# RL7005_IP_SVD register map
Vendor: Realtek
Registers are 32-bit, read-write, reset 0x0 unless marked. A register's access mark holds for its fields unless they carry their own. Offsets are from the block's base; [hi:lo] are bit positions; {n}, {i} and the like mark numbered series.

## UVC_REG
Base 0x400B1000
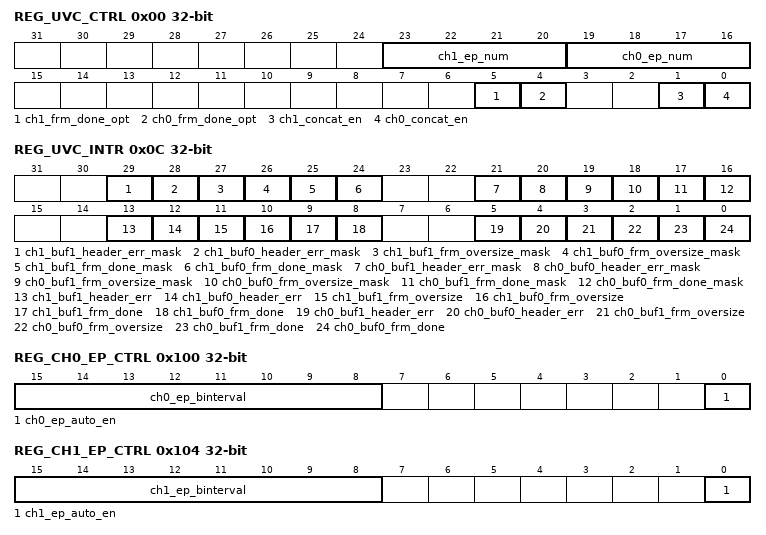
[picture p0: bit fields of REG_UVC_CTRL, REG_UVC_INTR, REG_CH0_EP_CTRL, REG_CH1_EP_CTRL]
0x00 REG_UVC_CTRL — Control Register
  [23:20] ch1_ep_num
  [19:16] ch0_ep_num
  [5] ch1_frm_done_opt — 1: frame_done when xfercomp at EOF flag 0: frame_done when frame id changing
  [4] ch0_frm_done_opt — 1: frame_done when xfercomp at EOF flag 0: frame_done when frame id changing
  [1] ch1_concat_en
  [0] ch0_concat_en
0x04 REG_UVC_CHNL0_CTRL — Channel_0 Control
  [31:0] ch0_dma_addr — For checking ahb xfer with header, this value should be the same as HCDMAi in otg_core
0x08 REG_UVC_CHNL1_CTRL — Channel_1 Control
  [31:0] ch1_dma_addr — For checking ahb xfer with header, this value should be the same as HCDMAi in otg_core
0x0C REG_UVC_INTR access per field — Interrupt Mask and Status
  [29] ch1_buf1_header_err_mask rw, [28] ch1_buf0_header_err_mask rw, [27] ch1_buf1_frm_oversize_mask rw, [26] ch1_buf0_frm_oversize_mask rw, [25] ch1_buf1_frm_done_mask rw, [24] ch1_buf0_frm_done_mask rw, [21] ch0_buf1_header_err_mask rw, [20] ch0_buf0_header_err_mask rw, [19] ch0_buf1_frm_oversize_mask rw, [18] ch0_buf0_frm_oversize_mask rw, [17] ch0_buf1_frm_done_mask rw, [16] ch0_buf0_frm_done_mask rw, [13] ch1_buf1_header_err ro, [12] ch1_buf0_header_err ro, [11] ch1_buf1_frm_oversize ro, [10] ch1_buf0_frm_oversize ro, [9] ch1_buf1_frm_done ro, [8] ch1_buf0_frm_done ro, [5] ch0_buf1_header_err ro, [4] ch0_buf0_header_err ro, [3] ch0_buf1_frm_oversize ro, [2] ch0_buf0_frm_oversize ro, [1] ch0_buf1_frm_done ro, [0] ch0_buf0_frm_done ro
0x10 REG_CH0_BUF0_START_ADDR
  [31:0] ch0_buf0_start_addr
0x14 REG_CH0_BUF0_END_ADDR
  [31:0] ch0_buf0_end_addr
0x18 REG_CH0_BUF0_FRM_SIZE ro
  [23:0] ch0_buf0_frm_size
0x1C REG_CH0_BUF0_PTS ro
  [31:0] ch0_buf0_pts
0x20 REG_CH0_BUF0_SCR_FIRST ro
  [31:0] ch0_buf0_scr_first
0x24 REG_CH0_BUF0_SCR_LAST ro
  [31:0] ch0_buf0_scr_last
0x28 REG_CH0_BUF0_SOF_CNT ro
  [15:0] ch0_buf0_sof_cnt
0x30 REG_CH0_BUF1_START_ADDR
  [31:0] ch0_buf1_start_addr
0x34 REG_CH0_BUF1_END_ADDR
  [31:0] ch0_buf1_end_addr
0x38 REG_CH0_BUF1_FRM_SIZE ro
  [23:0] ch0_buf1_frm_size
0x3C REG_CH0_BUF1_PTS ro
  [31:0] ch0_buf1_pts
0x40 REG_CH0_BUF1_SCR_FIRST ro
  [31:0] ch0_buf1_scr_first
0x44 REG_CH0_BUF1_SCR_LAST ro
  [31:0] ch0_buf1_scr_last
0x48 REG_CH0_BUF1_SOF_CNT ro
  [15:0] ch0_buf1_sof_cnt
0x50 REG_CH1_BUF0_START_ADDR
  [31:0] ch1_buf0_start_addr
0x54 REG_CH1_BUF0_END_ADDR
  [31:0] ch1_buf0_end_addr
0x58 REG_CH1_BUF0_FRM_SIZE ro
  [23:0] ch1_buf0_frm_size
0x5C REG_CH1_BUF0_PTS ro
  [31:0] ch1_buf0_pts
0x60 REG_CH1_BUF0_SCR_FIRST ro
  [31:0] ch1_buf0_scr_first
0x64 REG_CH1_BUF0_SCR_LAST ro
  [31:0] ch1_buf0_scr_last
0x68 REG_CH1_BUF0_SOF_CNT ro
  [15:0] ch1_buf0_sof_cnt
0x70 REG_CH1_BUF1_START_ADDR
  [31:0] ch1_buf1_start_addr
0x74 REG_CH1_BUF1_END_ADDR
  [31:0] ch1_buf1_end_addr
0x78 REG_CH1_BUF1_FRM_SIZE ro
  [23:0] ch1_buf1_frm_size
0x7C REG_CH1_BUF1_PTS ro
  [31:0] ch1_buf1_pts
0x80 REG_CH1_BUF1_SCR_FIRST ro
  [31:0] ch1_buf1_scr_first
0x84 REG_CH1_BUF1_SCR_LAST ro
  [31:0] ch1_buf1_scr_last
0x88 REG_CH1_BUF1_SOF_CNT ro
  [15:0] ch1_buf1_sof_cnt
0x100 REG_CH0_EP_CTRL — Channel_0 Endpoint Control
  [15:8] ch0_ep_binterval, [0] ch0_ep_auto_en
0x104 REG_CH1_EP_CTRL — Channel_1 Endpoint Control
  [15:8] ch1_ep_binterval, [0] ch1_ep_auto_en
0x10C REG_HST_FRREM_CTRL reset 0x10 — Host Frame Remain Threshold
  [15:0] hst_frremain_thresh — threshold for checking hst_frrem if hst_frrem(otg_core) > threshold, enable iso endpoint in this frame else, enable iso endpoint in next frame
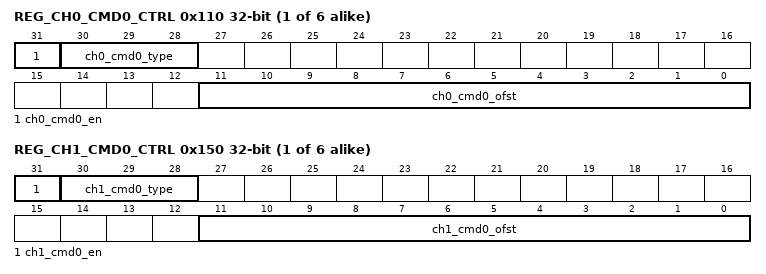
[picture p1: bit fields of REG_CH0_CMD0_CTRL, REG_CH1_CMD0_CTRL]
{0x110+8i} REG_CH0_CMD{i}_CTRL (i=0..5)
  [31] ch0_cmd{i}_en, [30:28] ch0_cmd{i}_type, [11:0] ch0_cmd{i}_ofst
{0x114+8i} REG_CH0_CMD{i}_DATA (i=0..5)
  [31:0] ch0_cmd{i}_data
{0x150+8i} REG_CH1_CMD{i}_CTRL (i=0..5)
  [31] ch1_cmd{i}_en, [30:28] ch1_cmd{i}_type, [11:0] ch1_cmd{i}_ofst
{0x154+8i} REG_CH1_CMD{i}_DATA (i=0..5)
  [31:0] ch1_cmd{i}_data
